# cyw20829 register map
Vendor: Infineon Technologies; Series: CYW20829; File version: 1.0
CPU: CM33 r0p1, little endian, MPU, no FPU, VTOR, 3 interrupt priority bits
Registers are 32-bit, read-write, reset 0x0 unless marked. A register's access mark holds for its fields unless they carry their own. Offsets are from the block's base; [hi:lo] are bit positions; lines under a group give offsets from that group; {n}, {i} and the like mark numbered series; 'fields as' and 'values as' point back to an identical list.

## ICACHE0 — CM33_0/1 CA APB interface
Base 0x40103000
Same registers: ICACHE1 0x40104000
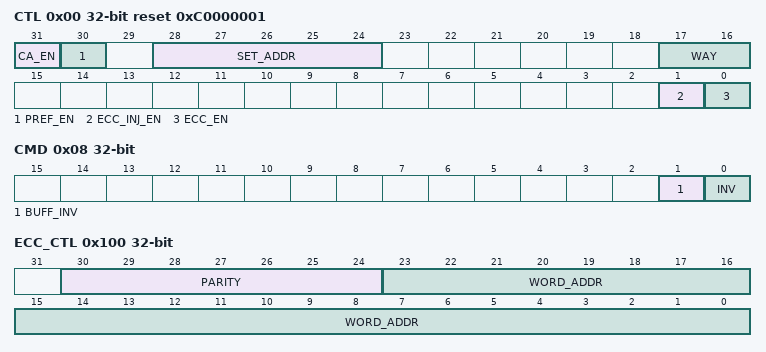
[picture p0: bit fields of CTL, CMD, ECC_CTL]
0x00 CTL reset 0xC0000001 — Cache control
  [31] CA_EN — Cache enable: 0: Disabled. The cache tag valid bits are reset to '0's and the cache LRU information is set to '1's (making way 0 the LRU way and way 3 the MRU way). 1: Enabled.
  [30] PREF_EN — Prefetch enable: 0: Disabled. 1: Enabled. Prefetching requires the cache to be enabled; i.e. ENABLED is '1'.
  [28:24] SET_ADDR — Specifies the cache set for which cache information is provided in STATUS0/1/2.
  [17:16] WAY — Specifies the cache way for which cache information is provided in STATUS0/1/2.
  [1] ECC_INJ_EN — Enable error injection for cache. When '1', the parity (ECC_CTL.PARITY[6:0]) is used when a cache refill is done to the ECC_CTL.WORD_ADDR[23:0] word address.
  [0] ECC_EN — Enable ECC checking for cache accesses: 0: Disabled. 1: Enabled.
0x08 CMD — Cache command
  [1] BUFF_INV — Invalidation of buffers (does not invalidate the caches). SW writes a '1' to clear the buffers. HW sets this field to '0' when the operation is completed.
  [0] INV — Invalidation of cahce and buffer. SW writes a '1' to clear the caches. HW sets this field to '0' when the operation is completed. The caches' LRU structures are also reset to their default state.
0x80 STATUS0 ro — Cache status 0
  [31:0] VALID32 — Sixteen valid bits of the cache line specified by CTL.WAY and CTL.SET_ADDR.
0x84 STATUS1 ro reset not defined — Cache status 1
  [31:0] TAG — Cache line address of the cache line specified by CTL.WAY and CTL.SET_ADDR.
0x88 STATUS2 ro reset not defined — Cache status 2
  [5:0] LRU — Six bit LRU representation of the cache set specified by CTL.SET_ADDR. The encoding of the field is as follows ('X_LRU_Y' indicates that way X is Less Recently Used than way Y): Bit 5: 0_LRU_1: way 0 less recently used than way 1. Bit 4: 0_LRU_2. Bit 3: 0_LRU_3. Bit 2: 1_LRU_2. Bit 1: 1_LRU_3. Bit 0: 2_LRU_3.
0x100 ECC_CTL — ECC control
  [30:24] PARITY — ECC parity to use for ECC error injection at address WORD_ADDR. - For cache SRAM ECC, the 7-bit parity PARITY[6:0] is for a 32-bit word.
  [23:0] WORD_ADDR — Specifies the word address where an error will be injected. - On a write transfer to this SRAM address and when the CTL.ECC_INJ_EN bit is '1', the parity (PARITY) is injected.

## CPUSS_SL_CTL — SYSCPUSS Internal slave control registers
Base 0x401C8000
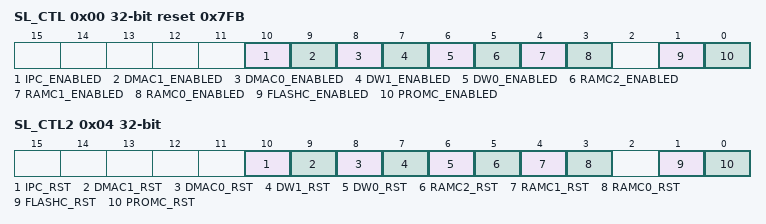
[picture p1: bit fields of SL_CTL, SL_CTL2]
0x00 SL_CTL reset 0x7FB — Slave control (Clock enables)
  [10] IPC_ENABLED
  [9] DMAC1_ENABLED
  [8] DMAC0_ENABLED
  [7] DW1_ENABLED
  [6] DW0_ENABLED
  [5] RAMC2_ENABLED
  [4] RAMC1_ENABLED
  [3] RAMC0_ENABLED
  [1] FLASHC_ENABLED
  [0] PROMC_ENABLED — Slave enable controls. Each bit indicates whether the respective slave is enabled or not. 0: Disabled 1: Enabled If the slave is disabled, its clock is gated off (constant '0'). Any access (MMIO AHB access or ROM/System SRAM memory access) to slave when disabled result in AHB error response.
0x04 SL_CTL2 — Slave control2 (Reset enables)
  [10] IPC_RST
  [9] DMAC1_RST
  [8] DMAC0_RST
  [7] DW1_RST
  [6] DW0_RST
  [5] RAMC2_RST
  [4] RAMC1_RST
  [3] RAMC0_RST
  [1] FLASHC_RST
  [0] PROMC_RST — Slave reset controls. Each bit indicates whether the respective slave reset is enabled or not. 0: Disabled 1: Enabled If the slave is under reset enabled state, its clock is gated off (constant '0') and its resets are in activated state (rst_n = 0) Any access (MMIO AHB access or ROM/System SRAM memory access) to slave when disabled result in AHB error response.

## IPC
Base 0x401D0000
{0x0+0x20*i} STRUCT[{i}] (i=0..3) group — IPC structure
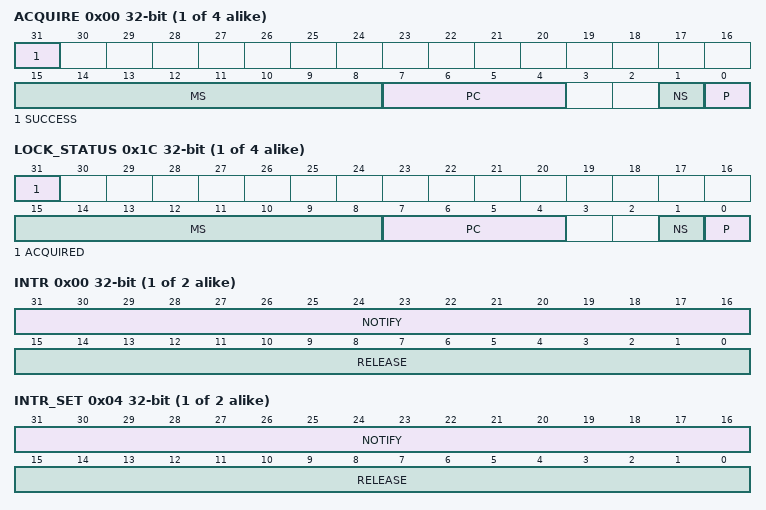
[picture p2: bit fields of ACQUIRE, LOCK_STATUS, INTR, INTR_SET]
  0x00 ACQUIRE ro (reset mask 0x80000000) — IPC acquire
    [31] SUCCESS
    [15:8] MS — This field specifies the bus master identifier that successfully acquired the lock.
    [7:4] PC
    [1] NS
    [0] P
  0x04 RELEASE wo — IPC release
    [15:0] INTR_RELEASE — Writing this field releases a lock and allows for the generation of release events to the IPC interrupt structures, but only when the lock is acquired (LOCK_STATUS.ACQUIRED is '1'). The IPC release cause fields associated with this IPC structure are set to '1', but only for those IPC interrupt structures for which the corresponding bit field in INTR_RELEASE[] is set to '1'. SW writes a '1' to the bit fields to generate a release event. Due to the transient nature of this event, SW always reads a '0' from this field.
  0x08 NOTIFY wo — IPC notification
    [15:0] INTR_NOTIFY — This field allows for the generation of notification events to the IPC interrupt structures. The IPC notification cause fields associated with this IPC structure are set to '1', but only for those IPC interrupt structures for which the corresponding bit field in INTR_NOTIFY[] is set to '1'. SW writes a '1' to the bit fields to generate a notify event. Due to the transient nature of this event, SW always reads a '0' from this field.
  0x0C DATA0 reset not defined — IPC data 0
    [31:0] DATA — This field holds a 32-bit data element that is associated with the IPC structure.
  0x10 DATA1 reset not defined — IPC data 1
    fields as STRUCT[0].DATA0
  0x1C LOCK_STATUS ro (reset mask 0x80000000) — IPC lock status
    [31] ACQUIRED
    [15:8] MS — This field specifies the bus master identifier that successfully acquired the lock.
    [7:4] PC
    [1] NS
    [0] P
{0x1000+0x20*i} INTR_STRUCT[{i}] (i=0..1) group — IPC interrupt structure
  0x00 INTR — Interrupt
    [31:16] NOTIFY — These interrupt cause fields are activated (HW sets the field to '1') when a IPC notification event is detected. One bit field for each master. SW writes a '1' to these field to clear the interrupt cause.
    [15:0] RELEASE — These interrupt cause fields are activated (HW sets the field to '1') when a IPC release event is detected. One bit field for each master. SW writes a '1' to these field to clear the interrupt cause.
  0x04 INTR_SET — Interrupt set
    [31:16] NOTIFY — SW writes a '1' to this field to set the corresponding field in the INTR register.
    [15:0] RELEASE — SW writes a '1' to this field to set the corresponding field in the INTR register.
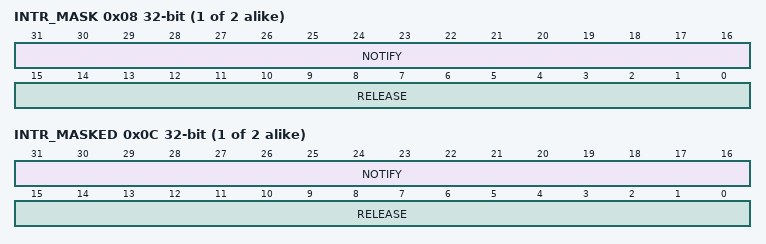
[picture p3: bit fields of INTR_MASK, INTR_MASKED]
  0x08 INTR_MASK — Interrupt mask
    [31:16] NOTIFY — Mask bit for corresponding field in the INTR register.
    [15:0] RELEASE — Mask bit for corresponding field in the INTR register.
  0x0C INTR_MASKED ro — Interrupt masked
    [31:16] NOTIFY — Logical and of corresponding INTR and INTR_MASK fields.
    [15:0] RELEASE — Logical and of corresponding request and mask bits.

## HSIOM — IO Matrix (IOM)
Base 0x40400000
{0x0+0x10*i} PRT[{i}] (i=0..5) group — HSIOM port registers
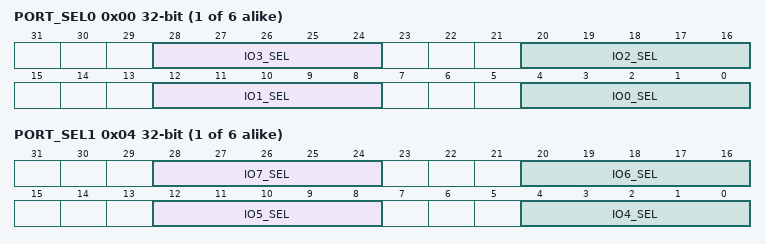
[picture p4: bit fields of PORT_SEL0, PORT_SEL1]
  0x00 PORT_SEL0 — Port selection 0
    [28:24] IO3_SEL — Selects connection for IO pin 3 route.
    [20:16] IO2_SEL — Selects connection for IO pin 2 route.
    [12:8] IO1_SEL — Selects connection for IO pin 1 route.
    [4:0] IO0_SEL — Selects connection for IO pin 0 route.
      0=GPIO (GPIO controls 'out'); 1=GPIO_DSI (GPIO controls 'out', DSI controls 'output enable'); 2=DSI_DSI (DSI controls 'out' and 'output enable'); 3=DSI_GPIO (DSI controls 'out', GPIO controls 'output enable'); 4=AMUXA (Analog mux bus A); 5=AMUXB (Analog mux bus B); 6=AMUXA_DSI (Analog mux bus A, DSI control); 7=AMUXB_DSI (Analog mux bus B, DSI control); {v}=ACT_{v-8} (Active functionality {v-8}) (v=8..11); {v}=DS_{v-12} (DeepSleep functionality {v-12}) (v=12..15); {v}=ACT_{v-12} (Active functionality {v-12}) (v=16..27); {v}=DS_{v-24} (DeepSleep functionality {v-24}) (v=28..31)
  0x04 PORT_SEL1 — Port selection 1
    [28:24] IO7_SEL — Selects connection for IO pin 7 route.
    [20:16] IO6_SEL — Selects connection for IO pin 6 route.
    [12:8] IO5_SEL — Selects connection for IO pin 5 route.
    [4:0] IO4_SEL — Selects connection for IO pin 4 route. See PORT_SEL0 for connection details.
{0x2200+4i} MONITOR_CTL_{i} (i=0..3) — Power/Ground Monitor cell control {i}
  [31:0] MONITOR_EN — control for switch, which connects the power/ground supply to AMUXBUS_A/B respectively when switch is closed: '0': switch open. '1': switch closed.

## CANFD0 (part 1 of 3) — CAN Controller
Base 0x40440000
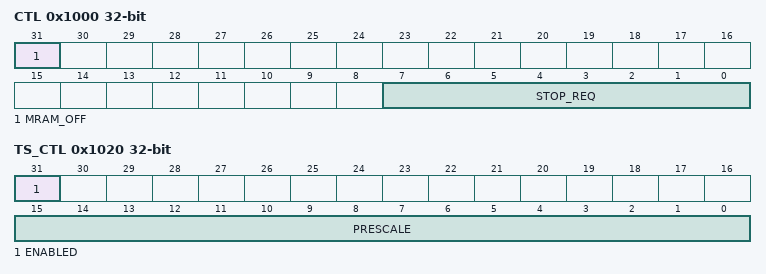
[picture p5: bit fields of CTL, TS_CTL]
0x1000 CTL — Global CAN control register
  [31] MRAM_OFF — MRAM off 0= Default MRAM on (with MRAM retained in DeepSleep). 1= Switch MRAM off (not retained) to save power. Before setting this bit all the CAN channels have to be powered down using the STOP_REQ/ACK bits. When the MRAM is off any access attempt to it is considered an address error (as if MRAM_SIZE=0). After switching the MRAM on again software needs to allow for a certain power up time before MRAM can be used, i.e. before STOP_REQ can be de-asserted. The power up time is equivalent to the system SRAM power up time specified in the CPUSS.RAM_PWR_DELAY_CTL register.
  [7:0] STOP_REQ
0x1004 STATUS ro — Global CAN status register
  [7:0] STOP_ACK — Clock Stop Acknowledge for each TTCAN IP. These bits are directly driven by m_ttcan_clkstop_ack of each TTCAN IP. When this bit is set the corresponding TTCAN IP clocks will be gated off, except HCLK will enabled for each AHB write
0x1010 INTR0_CAUSE ro — Consolidated interrupt0 cause register
  [7:0] INT0 — Show pending m_ttcan_int0 of each channel
0x1014 INTR1_CAUSE ro — Consolidated interrupt1 cause register
  [7:0] INT1 — Show pending m_ttcan_int1 of each channel
0x1020 TS_CTL — Time Stamp control register
  [31] ENABLED — Counter enable bit 0 = Count disabled. Stop counting up and keep the counter value 1 = Count enabled. Start counting up from the current value
  [15:0] PRESCALE — Time Stamp counter prescale value. When enabled divide the Host clock (HCLK) by PRESCALE+1 to create Time Stamp clock ticks.
0x1024 TS_CNT — Time Stamp counter value
  [15:0] VALUE — The counter value of the Time Stamp Counter. When enabled this counter will count Time Stamp clock ticks from the pre-scaler. When written this counter and the pre-scaler will reset to 0 (write data is ignored).
